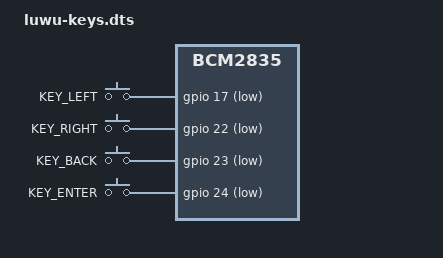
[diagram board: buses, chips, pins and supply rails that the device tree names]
/dts-v1/;
/plugin/;

/ {
    compatible = "brcm,bcm2835";

    fragment@0 {
        target-path = "/";
        __overlay__ {
            luwu_keys: luwu-keys {
                compatible = "gpio-keys";
                status = "okay";
                autorepeat;

                key_left: left {
                    label = "KEY_LEFT";
                    linux,code = <105>;
                    gpios = <&gpio 17 1>;
                    debounce-interval = <20>;
                };
                key_right: right {
                    label = "KEY_RIGHT";
                    linux,code = <106>;
                    gpios = <&gpio 22 1>;
                    debounce-interval = <20>;
                };
                key_back: back {
                    label = "KEY_BACK";
                    linux,code = <158>;
                    gpios = <&gpio 23 1>;
                    debounce-interval = <20>;
                };
                key_enter: enter {
                    label = "KEY_ENTER";
                    linux,code = <28>;
                    gpios = <&gpio 24 1>;
                    debounce-interval = <20>;
                };
            };
        };
    };
};
